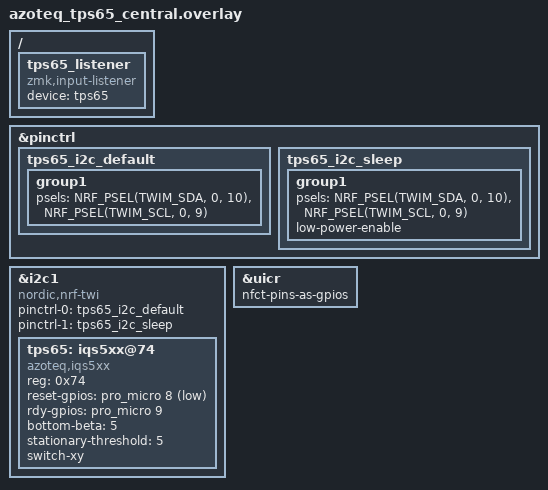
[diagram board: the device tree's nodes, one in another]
/* TPS65 on the LEFT: SDA D16/P0.10, SCL D10/P0.09,
 * NRST D8/P1.04, RDY D9/P1.06. Local input, no split pointer device. */
&pinctrl {
    tps65_i2c_default: tps65_i2c_default {
        group1 {
            psels = <NRF_PSEL(TWIM_SDA, 0, 10)>,
                    <NRF_PSEL(TWIM_SCL, 0, 9)>;
        };
    };

    tps65_i2c_sleep: tps65_i2c_sleep {
        group1 {
            psels = <NRF_PSEL(TWIM_SDA, 0, 10)>,
                    <NRF_PSEL(TWIM_SCL, 0, 9)>;
            low-power-enable;
        };
    };
};

&i2c1 {
    compatible = "nordic,nrf-twi";
    status = "okay";
    pinctrl-0 = <&tps65_i2c_default>;
    pinctrl-1 = <&tps65_i2c_sleep>;
    pinctrl-names = "default", "sleep";

    tps65: iqs5xx@74 {
        status = "okay";
        compatible = "azoteq,iqs5xx";
        reg = <0x74>;

        reset-gpios = <&pro_micro 8 GPIO_ACTIVE_LOW>;
        rdy-gpios = <&pro_micro 9 GPIO_ACTIVE_HIGH>;



        /* Movement only: no tap, hold, two-finger click or scrolling. */
        bottom-beta = <5>;
        stationary-threshold = <5>;

        switch-xy;
    };
};

/ {
    tps65_listener: tps65_listener {
        compatible = "zmk,input-listener";
        device = <&tps65>;
    };
};

/* P0.09/P0.10 are NFC pins until explicitly configured as GPIO. */
&uicr {
    nfct-pins-as-gpios;
};
